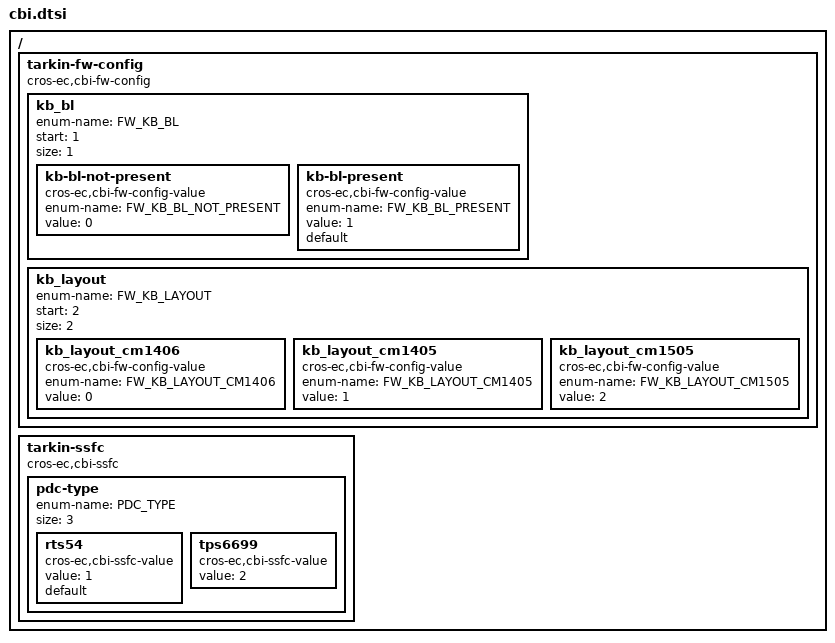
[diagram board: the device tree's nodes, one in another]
/* Copyright 2025 The ChromiumOS Authors
 * Use of this source code is governed by a BSD-style license that can be
 * found in the LICENSE file.
 */

/ {
	tarkin-fw-config {
		compatible = "cros-ec,cbi-fw-config";

		kb_bl {
			enum-name = "FW_KB_BL";
			start = <1>;
			size = <1>;
			kb-bl-not-present {
				compatible = "cros-ec,cbi-fw-config-value";
				enum-name = "FW_KB_BL_NOT_PRESENT";
				value = <0>;
			};
			kb-bl-present {
				compatible = "cros-ec,cbi-fw-config-value";
				enum-name = "FW_KB_BL_PRESENT";
				value = <1>;
                		default;
			};
		};

		kb_layout {
			enum-name = "FW_KB_LAYOUT";
			start = <2>;
			size = <2>;
			kb_layout_cm1406 {
				compatible = "cros-ec,cbi-fw-config-value";
				enum-name = "FW_KB_LAYOUT_CM1406";
				value = <0>;
			};
			kb_layout_cm1405 {
				compatible = "cros-ec,cbi-fw-config-value";
				enum-name = "FW_KB_LAYOUT_CM1405";
				value = <1>;
			};
			kb_layout_cm1505 {
				compatible = "cros-ec,cbi-fw-config-value";
				enum-name = "FW_KB_LAYOUT_CM1505";
				value = <2>;
			};
		};
	};

	tarkin-ssfc {
		compatible = "cros-ec,cbi-ssfc";

		/* SSFC field to identify PDC type.*/
		pdc-type {
			enum-name = "PDC_TYPE";
			size = <3>;

			rts54: rts54 {
				compatible = "cros-ec,cbi-ssfc-value";
				status = "okay";
				value = <1>;
				default;
			};
			tps6699: tps6699 {
				compatible = "cros-ec,cbi-ssfc-value";
				status = "okay";
				value = <2>;
			};
		};
	};
};
